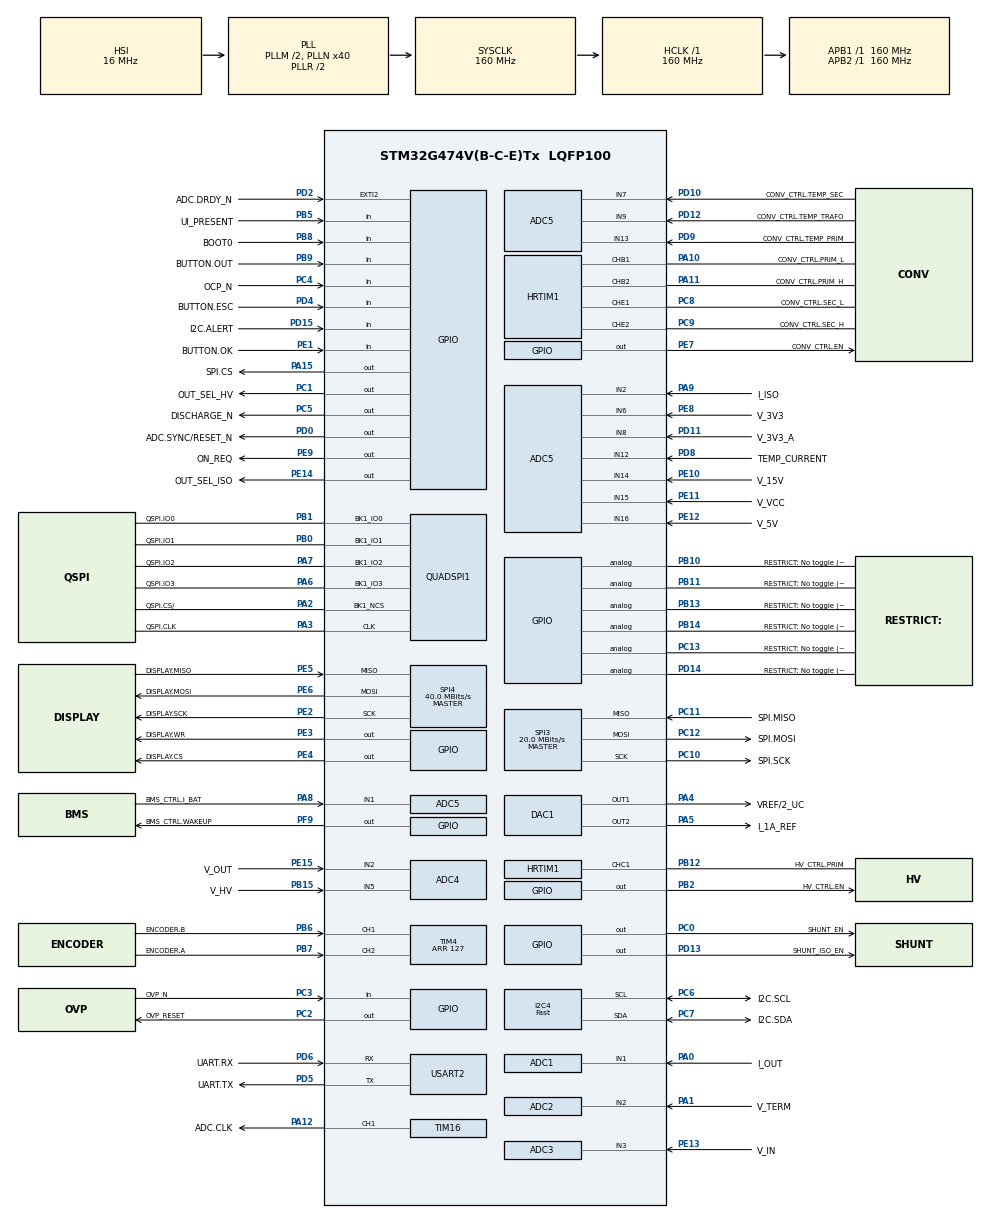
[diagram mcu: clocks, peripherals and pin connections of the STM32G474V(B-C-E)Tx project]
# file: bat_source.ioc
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ADC1.Channel-2\#ChannelRegularConversion=ADC_CHANNEL_1
ADC1.DMAContinuousRequests=ENABLE
ADC1.ExternalTrigConv=ADC_EXTERNALTRIG_HRTIM_TRG1
ADC1.NbrOfConversion=1
ADC1.NbrOfConversionFlag=1
ADC1.OffsetNumber-2\#ChannelRegularConversion=ADC_OFFSET_NONE
ADC1.Rank-2\#ChannelRegularConversion=1
ADC1.SamplingTime-2\#ChannelRegularConversion=ADC_SAMPLETIME_2CYCLES_5
ADC1.master=1
ADC2.Channel-0\#ChannelRegularConversion=ADC_CHANNEL_2
ADC2.DMAContinuousRequests=ENABLE
ADC2.ExternalTrigConv=ADC_EXTERNALTRIG_HRTIM_TRG1
ADC2.NbrOfConversionFlag=1
ADC2.OffsetNumber-0\#ChannelRegularConversion=ADC_OFFSET_NONE
ADC2.Rank-0\#ChannelRegularConversion=1
ADC2.SamplingTime-0\#ChannelRegularConversion=ADC_SAMPLETIME_2CYCLES_5
ADC3.Channel-2\#ChannelRegularConversion=ADC_CHANNEL_3
ADC3.DMAContinuousRequests=ENABLE
ADC3.EnableRegularConversion=ENABLE
ADC3.ExternalTrigConv=ADC_EXTERNALTRIG_HRTIM_TRG1
ADC3.NbrOfConversionFlag=1
ADC3.OffsetNumber-2\#ChannelRegularConversion=ADC_OFFSET_NONE
ADC3.Rank-2\#ChannelRegularConversion=1
ADC3.SamplingTime-2\#ChannelRegularConversion=ADC_SAMPLETIME_2CYCLES_5
ADC3.master=1
ADC4.Channel-0\#ChannelRegularConversion=ADC_CHANNEL_5
ADC4.DMAContinuousRequests=ENABLE
ADC4.EnableInjectedConversion=DISABLE
ADC4.ExternalTrigConv=ADC_EXTERNALTRIG_HRTIM_TRG1
ADC4.NbrOfConversionFlag=1
ADC4.OffsetNumber-0\#ChannelRegularConversion=ADC_OFFSET_NONE
ADC4.Rank-0\#ChannelRegularConversion=1
ADC4.Rank1_Channel=ADC_CHANNEL_2
ADC4.SamplingTime-0\#ChannelRegularConversion=ADC_SAMPLETIME_2CYCLES_5
ADC5.Channel-0\#ChannelRegularConversion=ADC_CHANNEL_6
ADC5.Channel-10\#ChannelRegularConversion=ADC_CHANNEL_TEMPSENSOR_ADC5
ADC5.Channel-11\#ChannelRegularConversion=ADC_CHANNEL_VBAT
ADC5.Channel-12\#ChannelRegularConversion=ADC_CHANNEL_VREFINT
ADC5.Channel-2\#ChannelRegularConversion=ADC_CHANNEL_7
ADC5.Channel-3\#ChannelRegularConversion=ADC_CHANNEL_8
ADC5.Channel-4\#ChannelRegularConversion=ADC_CHANNEL_9
ADC5.Channel-5\#ChannelRegularConversion=ADC_CHANNEL_12
ADC5.Channel-6\#ChannelRegularConversion=ADC_CHANNEL_13
ADC5.Channel-7\#ChannelRegularConversion=ADC_CHANNEL_14
ADC5.Channel-8\#ChannelRegularConversion=ADC_CHANNEL_15
ADC5.Channel-9\#ChannelRegularConversion=ADC_CHANNEL_16
ADC5.ContinuousConvMode=ENABLE
ADC5.DMAContinuousRequests=ENABLE
ADC5.DiscontinuousConvMode=DISABLE
ADC5.EOCSelection=ADC_EOC_SINGLE_CONV
ADC5.EnableInjectedConversion=ENABLE
ADC5.ExternalTrigInjecConv=ADC_EXTERNALTRIGINJEC_HRTIM_TRG1
ADC5.InjNumberOfConversion=1
ADC5.InjectedChannel-13\#ChannelInjectedConversion=ADC_CHANNEL_1
ADC5.InjectedOffsetNumber-13\#ChannelInjectedConversion=ADC_OFFSET_NONE
ADC5.InjectedRank-13\#ChannelInjectedConversion=1
ADC5.InjectedSamplingTime-13\#ChannelInjectedConversion=ADC_SAMPLETIME_2CYCLES_5
ADC5.NbrOfConversion=12
ADC5.NbrOfConversionFlag=1
ADC5.OffsetNumber-0\#ChannelRegularConversion=ADC_OFFSET_NONE
ADC5.OffsetNumber-10\#ChannelRegularConversion=ADC_OFFSET_NONE
ADC5.OffsetNumber-11\#ChannelRegularConversion=ADC_OFFSET_NONE
ADC5.OffsetNumber-12\#ChannelRegularConversion=ADC_OFFSET_NONE
ADC5.OffsetNumber-2\#ChannelRegularConversion=ADC_OFFSET_NONE
ADC5.OffsetNumber-3\#ChannelRegularConversion=ADC_OFFSET_NONE
ADC5.OffsetNumber-4\#ChannelRegularConversion=ADC_OFFSET_NONE
ADC5.OffsetNumber-5\#ChannelRegularConversion=ADC_OFFSET_NONE
ADC5.OffsetNumber-6\#ChannelRegularConversion=ADC_OFFSET_NONE
ADC5.OffsetNumber-7\#ChannelRegularConversion=ADC_OFFSET_NONE
ADC5.OffsetNumber-8\#ChannelRegularConversion=ADC_OFFSET_NONE
ADC5.OffsetNumber-9\#ChannelRegularConversion=ADC_OFFSET_NONE
ADC5.OversamplingMode=ENABLE
ADC5.Rank-0\#ChannelRegularConversion=1
ADC5.Rank-10\#ChannelRegularConversion=10
ADC5.Rank-11\#ChannelRegularConversion=11
ADC5.Rank-12\#ChannelRegularConversion=12
ADC5.Rank-2\#ChannelRegularConversion=2
ADC5.Rank-3\#ChannelRegularConversion=3
ADC5.Rank-4\#ChannelRegularConversion=4
ADC5.Rank-5\#ChannelRegularConversion=5
ADC5.Rank-6\#ChannelRegularConversion=6
ADC5.Rank-7\#ChannelRegularConversion=7
ADC5.Rank-8\#ChannelRegularConversion=8
ADC5.Rank-9\#ChannelRegularConversion=9
ADC5.Rank1_Channel=ADC_CHANNEL_1
ADC5.Ratio=ADC_OVERSAMPLING_RATIO_256
ADC5.RightBitShift=ADC_RIGHTBITSHIFT_4
ADC5.SamplingTime-0\#ChannelRegularConversion=ADC_SAMPLETIME_2CYCLES_5
ADC5.SamplingTime-10\#ChannelRegularConversion=ADC_SAMPLETIME_2CYCLES_5
ADC5.SamplingTime-11\#ChannelRegularConversion=ADC_SAMPLETIME_2CYCLES_5
ADC5.SamplingTime-12\#ChannelRegularConversion=ADC_SAMPLETIME_2CYCLES_5
ADC5.SamplingTime-2\#ChannelRegularConversion=ADC_SAMPLETIME_2CYCLES_5
ADC5.SamplingTime-3\#ChannelRegularConversion=ADC_SAMPLETIME_2CYCLES_5
ADC5.SamplingTime-4\#ChannelRegularConversion=ADC_SAMPLETIME_2CYCLES_5
ADC5.SamplingTime-5\#ChannelRegularConversion=ADC_SAMPLETIME_2CYCLES_5
ADC5.SamplingTime-6\#ChannelRegularConversion=ADC_SAMPLETIME_2CYCLES_5
ADC5.SamplingTime-7\#ChannelRegularConversion=ADC_SAMPLETIME_2CYCLES_5
ADC5.SamplingTime-8\#ChannelRegularConversion=ADC_SAMPLETIME_2CYCLES_5
ADC5.SamplingTime-9\#ChannelRegularConversion=ADC_SAMPLETIME_2CYCLES_5
DAC1.DAC_Channel-DAC_OUT2=DAC_CHANNEL_2
Dma.ADC1.1.Direction=DMA_PERIPH_TO_MEMORY
Dma.ADC1.1.EventEnable=DISABLE
Dma.ADC1.1.Instance=DMA1_Channel2
Dma.ADC1.1.MemDataAlignment=DMA_MDATAALIGN_HALFWORD
Dma.ADC1.1.MemInc=DMA_MINC_ENABLE
Dma.ADC1.1.Mode=DMA_CIRCULAR
Dma.ADC1.1.PeriphDataAlignment=DMA_PDATAALIGN_HALFWORD
Dma.ADC1.1.PeriphInc=DMA_PINC_DISABLE
Dma.ADC1.1.Polarity=HAL_DMAMUX_REQ_GEN_RISING
Dma.ADC1.1.Priority=DMA_PRIORITY_LOW
Dma.ADC1.1.RequestNumber=1
Dma.ADC1.1.SignalID=NONE
Dma.ADC1.1.SyncEnable=DISABLE
Dma.ADC1.1.SyncPolarity=HAL_DMAMUX_SYNC_NO_EVENT
Dma.ADC1.1.SyncRequestNumber=1
Dma.ADC1.1.SyncSignalID=NONE
Dma.ADC2.2.Direction=DMA_PERIPH_TO_MEMORY
Dma.ADC2.2.EventEnable=DISABLE
Dma.ADC2.2.Instance=DMA1_Channel3
Dma.ADC2.2.MemDataAlignment=DMA_MDATAALIGN_HALFWORD
Dma.ADC2.2.MemInc=DMA_MINC_ENABLE
Dma.ADC2.2.Mode=DMA_CIRCULAR
Dma.ADC2.2.PeriphDataAlignment=DMA_PDATAALIGN_HALFWORD
Dma.ADC2.2.PeriphInc=DMA_PINC_DISABLE
Dma.ADC2.2.Polarity=HAL_DMAMUX_REQ_GEN_RISING
Dma.ADC2.2.Priority=DMA_PRIORITY_LOW
Dma.ADC2.2.RequestNumber=1
Dma.ADC2.2.SignalID=NONE
Dma.ADC2.2.SyncEnable=DISABLE
Dma.ADC2.2.SyncPolarity=HAL_DMAMUX_SYNC_NO_EVENT
Dma.ADC2.2.SyncRequestNumber=1
Dma.ADC2.2.SyncSignalID=NONE
Dma.ADC3.3.Direction=DMA_PERIPH_TO_MEMORY
Dma.ADC3.3.EventEnable=DISABLE
Dma.ADC3.3.Instance=DMA1_Channel4
Dma.ADC3.3.MemDataAlignment=DMA_MDATAALIGN_HALFWORD
Dma.ADC3.3.MemInc=DMA_MINC_ENABLE
Dma.ADC3.3.Mode=DMA_CIRCULAR
Dma.ADC3.3.PeriphDataAlignment=DMA_PDATAALIGN_HALFWORD
Dma.ADC3.3.PeriphInc=DMA_PINC_DISABLE
Dma.ADC3.3.Polarity=HAL_DMAMUX_REQ_GEN_RISING
Dma.ADC3.3.Priority=DMA_PRIORITY_LOW
Dma.ADC3.3.RequestNumber=1
Dma.ADC3.3.SignalID=NONE
Dma.ADC3.3.SyncEnable=DISABLE
Dma.ADC3.3.SyncPolarity=HAL_DMAMUX_SYNC_NO_EVENT
Dma.ADC3.3.SyncRequestNumber=1
Dma.ADC3.3.SyncSignalID=NONE
Dma.ADC4.4.Direction=DMA_PERIPH_TO_MEMORY
Dma.ADC4.4.EventEnable=DISABLE
Dma.ADC4.4.Instance=DMA1_Channel5
Dma.ADC4.4.MemDataAlignment=DMA_MDATAALIGN_HALFWORD
Dma.ADC4.4.MemInc=DMA_MINC_ENABLE
Dma.ADC4.4.Mode=DMA_CIRCULAR
Dma.ADC4.4.PeriphDataAlignment=DMA_PDATAALIGN_HALFWORD
Dma.ADC4.4.PeriphInc=DMA_PINC_DISABLE
Dma.ADC4.4.Polarity=HAL_DMAMUX_REQ_GEN_RISING
Dma.ADC4.4.Priority=DMA_PRIORITY_LOW
Dma.ADC4.4.RequestNumber=1
Dma.ADC4.4.SignalID=NONE
Dma.ADC4.4.SyncEnable=DISABLE
Dma.ADC4.4.SyncPolarity=HAL_DMAMUX_SYNC_NO_EVENT
Dma.ADC4.4.SyncRequestNumber=1
Dma.ADC4.4.SyncSignalID=NONE
Dma.ADC5.0.Direction=DMA_PERIPH_TO_MEMORY
Dma.ADC5.0.EventEnable=DISABLE
Dma.ADC5.0.Instance=DMA1_Channel1
Dma.ADC5.0.MemDataAlignment=DMA_MDATAALIGN_HALFWORD
Dma.ADC5.0.MemInc=DMA_MINC_ENABLE
Dma.ADC5.0.Mode=DMA_CIRCULAR
Dma.ADC5.0.PeriphDataAlignment=DMA_PDATAALIGN_HALFWORD
Dma.ADC5.0.PeriphInc=DMA_PINC_DISABLE
Dma.ADC5.0.Polarity=HAL_DMAMUX_REQ_GEN_RISING
Dma.ADC5.0.Priority=DMA_PRIORITY_LOW
Dma.ADC5.0.RequestNumber=1
Dma.ADC5.0.SignalID=NONE
Dma.ADC5.0.SyncEnable=DISABLE
Dma.ADC5.0.SyncPolarity=HAL_DMAMUX_SYNC_NO_EVENT
Dma.ADC5.0.SyncRequestNumber=1
Dma.ADC5.0.SyncSignalID=NONE
Dma.I2C4_RX.7.Direction=DMA_PERIPH_TO_MEMORY
Dma.I2C4_RX.7.EventEnable=DISABLE
Dma.I2C4_RX.7.Instance=DMA1_Channel8
Dma.I2C4_RX.7.MemDataAlignment=DMA_MDATAALIGN_BYTE
Dma.I2C4_RX.7.MemInc=DMA_MINC_ENABLE
Dma.I2C4_RX.7.Mode=DMA_NORMAL
Dma.I2C4_RX.7.PeriphDataAlignment=DMA_PDATAALIGN_BYTE
Dma.I2C4_RX.7.PeriphInc=DMA_PINC_DISABLE
Dma.I2C4_RX.7.Polarity=HAL_DMAMUX_REQ_GEN_RISING
Dma.I2C4_RX.7.Priority=DMA_PRIORITY_LOW
Dma.I2C4_RX.7.RequestNumber=1
Dma.I2C4_RX.7.SignalID=NONE
Dma.I2C4_RX.7.SyncEnable=DISABLE
Dma.I2C4_RX.7.SyncPolarity=HAL_DMAMUX_SYNC_NO_EVENT
Dma.I2C4_RX.7.SyncRequestNumber=1
Dma.I2C4_RX.7.SyncSignalID=NONE
Dma.I2C4_TX.8.Direction=DMA_MEMORY_TO_PERIPH
Dma.I2C4_TX.8.EventEnable=DISABLE
Dma.I2C4_TX.8.Instance=DMA2_Channel1
Dma.I2C4_TX.8.MemDataAlignment=DMA_MDATAALIGN_BYTE
Dma.I2C4_TX.8.MemInc=DMA_MINC_ENABLE
Dma.I2C4_TX.8.Mode=DMA_NORMAL
Dma.I2C4_TX.8.PeriphDataAlignment=DMA_PDATAALIGN_BYTE
Dma.I2C4_TX.8.PeriphInc=DMA_PINC_DISABLE
Dma.I2C4_TX.8.Polarity=HAL_DMAMUX_REQ_GEN_RISING
Dma.I2C4_TX.8.Priority=DMA_PRIORITY_LOW
Dma.I2C4_TX.8.RequestNumber=1
Dma.I2C4_TX.8.SignalID=NONE
Dma.I2C4_TX.8.SyncEnable=DISABLE
Dma.I2C4_TX.8.SyncPolarity=HAL_DMAMUX_SYNC_NO_EVENT
Dma.I2C4_TX.8.SyncRequestNumber=1
Dma.I2C4_TX.8.SyncSignalID=NONE
Dma.Request0=ADC5
Dma.Request1=ADC1
Dma.Request2=ADC2
Dma.Request3=ADC3
Dma.Request4=ADC4
Dma.Request5=SPI3_RX
Dma.Request6=SPI3_TX
Dma.Request7=I2C4_RX
Dma.Request8=I2C4_TX
Dma.Request9=SPI4_TX
Dma.SPI3_RX.5.Direction=DMA_PERIPH_TO_MEMORY
Dma.SPI3_RX.5.EventEnable=DISABLE
Dma.SPI3_RX.5.Instance=DMA1_Channel6
Dma.SPI3_RX.5.MemDataAlignment=DMA_MDATAALIGN_BYTE
Dma.SPI3_RX.5.MemInc=DMA_MINC_ENABLE
Dma.SPI3_RX.5.Mode=DMA_NORMAL
Dma.SPI3_RX.5.PeriphDataAlignment=DMA_PDATAALIGN_BYTE
Dma.SPI3_RX.5.PeriphInc=DMA_PINC_DISABLE
Dma.SPI3_RX.5.Polarity=HAL_DMAMUX_REQ_GEN_RISING
Dma.SPI3_RX.5.Priority=DMA_PRIORITY_LOW
Dma.SPI3_RX.5.RequestNumber=1
Dma.SPI3_RX.5.SignalID=NONE
Dma.SPI3_RX.5.SyncEnable=DISABLE
Dma.SPI3_RX.5.SyncPolarity=HAL_DMAMUX_SYNC_NO_EVENT
Dma.SPI3_RX.5.SyncRequestNumber=1
Dma.SPI3_RX.5.SyncSignalID=NONE
Dma.SPI3_TX.6.Direction=DMA_MEMORY_TO_PERIPH
Dma.SPI3_TX.6.EventEnable=DISABLE
Dma.SPI3_TX.6.Instance=DMA1_Channel7
Dma.SPI3_TX.6.MemDataAlignment=DMA_MDATAALIGN_BYTE
Dma.SPI3_TX.6.MemInc=DMA_MINC_ENABLE
Dma.SPI3_TX.6.Mode=DMA_NORMAL
Dma.SPI3_TX.6.PeriphDataAlignment=DMA_PDATAALIGN_BYTE
Dma.SPI3_TX.6.PeriphInc=DMA_PINC_DISABLE
Dma.SPI3_TX.6.Polarity=HAL_DMAMUX_REQ_GEN_RISING
Dma.SPI3_TX.6.Priority=DMA_PRIORITY_LOW
Dma.SPI3_TX.6.RequestNumber=1
Dma.SPI3_TX.6.SignalID=NONE
Dma.SPI3_TX.6.SyncEnable=DISABLE
Dma.SPI3_TX.6.SyncPolarity=HAL_DMAMUX_SYNC_NO_EVENT
Dma.SPI3_TX.6.SyncRequestNumber=1
Dma.SPI3_TX.6.SyncSignalID=NONE
Dma.SPI4_TX.9.Direction=DMA_MEMORY_TO_PERIPH
Dma.SPI4_TX.9.EventEnable=DISABLE
Dma.SPI4_TX.9.Instance=DMA2_Channel2
Dma.SPI4_TX.9.MemDataAlignment=DMA_MDATAALIGN_BYTE
Dma.SPI4_TX.9.MemInc=DMA_MINC_ENABLE
Dma.SPI4_TX.9.Mode=DMA_NORMAL
Dma.SPI4_TX.9.PeriphDataAlignment=DMA_PDATAALIGN_BYTE
Dma.SPI4_TX.9.PeriphInc=DMA_PINC_DISABLE
Dma.SPI4_TX.9.Polarity=HAL_DMAMUX_REQ_GEN_RISING
Dma.SPI4_TX.9.Priority=DMA_PRIORITY_LOW
Dma.SPI4_TX.9.RequestNumber=1
Dma.SPI4_TX.9.SignalID=NONE
Dma.SPI4_TX.9.SyncEnable=DISABLE
Dma.SPI4_TX.9.SyncPolarity=HAL_DMAMUX_SYNC_NO_EVENT
Dma.SPI4_TX.9.SyncRequestNumber=1
Dma.SPI4_TX.9.SyncSignalID=NONE
HRTIM1.ADCTrigger1_Source1=HRTIM_ADCTRIGGEREVENT13_TIMERB_PERIOD
HRTIM1.ADCTrigger3_Source1=HRTIM_ADCTRIGGEREVENT13_TIMERE_PERIOD
HRTIM1.ADCTrigger_Id1=HRTIM_ADCTRIGGER_1
HRTIM1.ADCTrigger_Id2=__NULL
HRTIM1.ADCTrigger_Id3=HRTIM_ADCTRIGGER_3
HRTIM1.ADCTrigger_Id5=HRTIM_ADCTRIGGER_5
HRTIM1.ADCTrigger_Id6=__NULL
HRTIM1.ADCTrigger_Id7=HRTIM_ADCTRIGGER_7
HRTIM1.ADCTrigger_Id8=__NULL
HRTIM1.Adrom_TB=HRTIM_TIM_ADROM_CREST
HRTIM1.Adrom_TC=HRTIM_TIM_ADROM_CREST
HRTIM1.Adrom_TD=HRTIM_TIM_ADROM_CREST
HRTIM1.Adrom_TE=HRTIM_TIM_ADROM_CREST
HRTIM1.BURSTMODEPeriod=20
HRTIM1.BurstPreloadEnable=HRIM_BURSTMODEPRELOAD_DISABLED
HRTIM1.ClockSource=HRTIM_BURSTMODECLOCKSOURCE_TIMER_D
HRTIM1.CompareUnit1-MasterTimer=HRTIM_COMPAREUNIT_1
HRTIM1.CompareUnit1-Output_TB1TB2=HRTIM_COMPAREUNIT_1
HRTIM1.CompareUnit1-Output_TC1=HRTIM_COMPAREUNIT_1
HRTIM1.CompareUnit1-Output_TE1TE2=HRTIM_COMPAREUNIT_1
HRTIM1.CompareUnit2-MasterTimer=HRTIM_COMPAREUNIT_2
HRTIM1.CompareUnit2-Output_TB1TB2=__NULL
HRTIM1.CompareUnit3-MasterTimer=HRTIM_COMPAREUNIT_3
HRTIM1.CompareValue1-MasterTimer=5120
HRTIM1.CompareValue1-Output_TB1TB2=0x60
HRTIM1.CompareValue1-Output_TC1=0x1555
HRTIM1.CompareValue1-Output_TE1TE2=0x300
HRTIM1.CompareValue2-MasterTimer=26880
HRTIM1.CompareValue3-MasterTimer=30720
HRTIM1.Configuration_TB=Waveform
HRTIM1.Configuration_TC=Waveform
HRTIM1.Configuration_TD=Simple
HRTIM1.DeadTimeInsertion-Output_TB1TB2=HRTIM_TIMDEADTIMEINSERTION_ENABLED
HRTIM1.DeadTimeInsertion-Output_TE1TE2=HRTIM_TIMDEADTIMEINSERTION_ENABLED
HRTIM1.Deadtimeconfig-Output_TB1TB2=HRTIM_TIMERINDEX_TIMER_B
HRTIM1.Enable=HRTIM_BURSTMODECTL_ENABLED
HRTIM1.Event_EEV1=__NULL
HRTIM1.FallingLock-Output_TB1TB2=HRTIM_TIMDEADTIME_FALLINGLOCK_READONLY
HRTIM1.FallingLock-Output_TE1TE2=HRTIM_TIMDEADTIME_FALLINGLOCK_READONLY
HRTIM1.FallingSignLock-Output_TB1TB2=HRTIM_TIMDEADTIME_FALLINGSIGNLOCK_READONLY
HRTIM1.FallingSignLock-Output_TE1TE2=HRTIM_TIMDEADTIME_FALLINGSIGNLOCK_READONLY
HRTIM1.FallingValue-Output_TB1TB2=0x00A
HRTIM1.FallingValue-Output_TE1TE2=0x00A
HRTIM1.GreaterCMP1_TB=HRTIM_TIMERGTCMP1_EQUAL
HRTIM1.GreaterCMP1_TE=HRTIM_TIMERGTCMP1_EQUAL
HRTIM1.Mode=HRTIM_BURSTMODE_CONTINOUS
HRTIM1.ModeTimeBase-Output_TE1TE2=HRTIM_MODE_CONTINUOUS
HRTIM1.NumberADCTriggerSource1=1
HRTIM1.NumberADCTriggerSource3=1
HRTIM1.NumberResetSource1-Output_TB1TB2=1
HRTIM1.NumberResetSource1-Output_TC1=1
HRTIM1.NumberResetSource1-Output_TE1TE2=1
HRTIM1.NumberResetTrigger-Output_TB1TB2=0
HRTIM1.NumberResetTrigger-Output_TE1TE2=0
HRTIM1.NumberSetSource1-Output_TB1TB2=1
HRTIM1.NumberSetSource1-Output_TC1=0
HRTIM1.NumberSetSource1-Output_TE1TE2=0
HRTIM1.NumberUpdateTrigger-Output_TB1TB2=1
HRTIM1.NumberUpdateTrigger-Output_TE1TE2=1
HRTIM1.ORingUpdateSource_ADCTrigger1=HRTIM_ADCTRIGGERUPDATE_TIMER_B
HRTIM1.ORingUpdateSource_ADCTrigger3=HRTIM_ADCTRIGGERUPDATE_TIMER_E
HRTIM1.ORingUpdateSource_ADCTrigger5=HRTIM_ADCTRIGGERUPDATE_TIMER_C
HRTIM1.ORingUpdateSource_ADCTrigger7=HRTIM_ADCTRIGGERUPDATE_TIMER_D
HRTIM1.Periode_MASTER=51200
HRTIM1.Periode_TB=51200
HRTIM1.Periode_TC=0x3924
HRTIM1.Periode_TD=2560
HRTIM1.Periode_TE=0xC800
HRTIM1.PreloadEnable-Output_TB1TB2=HRTIM_PRELOAD_ENABLED
HRTIM1.PreloadEnable-Output_TE1TE2=HRTIM_PRELOAD_ENABLED
HRTIM1.PrescalerRatio_MASTER=HRTIM_PRESCALERRATIO_MUL16
HRTIM1.PrescalerRatio_TE=HRTIM_PRESCALERRATIO_MUL32
HRTIM1.ReSyncUpdate-Output_TB1TB2=HRTIM_TIMERESYNC_UPDATE_CONDITIONAL
HRTIM1.ReSyncUpdate-Output_TE1TE2=HRTIM_TIMERESYNC_UPDATE_CONDITIONAL
HRTIM1.RepetitionUpdate-Output_TB1TB2=HRTIM_UPDATEONREPETITION_DISABLED
HRTIM1.ResetOutput1_Source1-Output_TC1=HRTIM_OUTPUTRESET_TIMCMP1
HRTIM1.ResetOutput1_Source1-Output_TE1TE2=HRTIM_OUTPUTRESET_TIMCMP1
HRTIM1.ResetUpdate-Output_TB1TB2=HRTIM_TIMUPDATEONRESET_ENABLED
HRTIM1.ResetUpdate-Output_TE1TE2=HRTIM_TIMUPDATEONRESET_ENABLED
HRTIM1.RisingLock-Output_TB1TB2=HRTIM_TIMDEADTIME_RISINGLOCK_READONLY
HRTIM1.RisingLock-Output_TE1TE2=HRTIM_TIMDEADTIME_RISINGLOCK_READONLY
HRTIM1.RisingSignLock-Output_TB1TB2=HRTIM_TIMDEADTIME_RISINGSIGNLOCK_READONLY
HRTIM1.RisingSignLock-Output_TE1TE2=HRTIM_TIMDEADTIME_RISINGSIGNLOCK_READONLY
HRTIM1.RisingValue-Output_TB1TB2=0x00A
HRTIM1.RisingValue-Output_TE1TE2=0x00A
HRTIM1.SetOutput1_Source1-Output_TB1TB2=HRTIM_OUTPUTSET_TIMCMP1
HRTIM1.Source_ADCTrigger5=HRTIM_ADCTRIGGEREVENT579_TIMERC_PERIOD
HRTIM1.Source_ADCTrigger7=HRTIM_ADCTRIGGEREVENT579_TIMERD_PERIOD
HRTIM1.UpDownMode-No_output_TD=HRTIM_TIMERUPDOWNMODE_UPDOWN
HRTIM1.UpDownMode-Output_TB1TB2=HRTIM_TIMERUPDOWNMODE_UPDOWN
HRTIM1.UpDownMode-Output_TC1=HRTIM_TIMERUPDOWNMODE_UPDOWN
HRTIM1.UpDownMode-Output_TE1TE2=HRTIM_TIMERUPDOWNMODE_UPDOWN
HRTIM1.UpdateTrigger1-Output_TB1TB2=HRTIM_TIMUPDATETRIGGER_TIMER_B
HRTIM1.UpdateTrigger1-Output_TE1TE2=HRTIM_TIMUPDATETRIGGER_TIMER_E
HRTIM1.postscaler1=19
HRTIM1.postscaler3=19
HRTIM1.postscaler5=0x6
HRTIM1.postscaler7=19
I2C4.I2C_Speed_Mode=I2C_Fast
I2C4.Speed=400
I2C4.Timing=0x10F32A82
Mcu.Family=STM32G4
Mcu.Name=STM32G474V(B-C-E)Tx
Mcu.Package=LQFP100
NVIC.DMA1_Channel1_IRQn=true\:4\:0\:false\:false\:true\:false\:true\:true
NVIC.DMA1_Channel2_IRQn=true\:0\:0\:false\:false\:true\:false\:true\:true
NVIC.DMA1_Channel3_IRQn=true\:4\:0\:false\:false\:true\:false\:true\:true
NVIC.DMA1_Channel4_IRQn=true\:4\:0\:false\:false\:true\:false\:true\:true
NVIC.DMA1_Channel5_IRQn=true\:4\:0\:false\:false\:true\:false\:true\:true
NVIC.DMA1_Channel6_IRQn=true\:4\:0\:false\:false\:true\:false\:true\:true
NVIC.DMA1_Channel7_IRQn=true\:4\:0\:false\:false\:true\:false\:true\:true
NVIC.DMA1_Channel8_IRQn=true\:8\:0\:false\:false\:true\:false\:true\:true
NVIC.DMA2_Channel1_IRQn=true\:8\:0\:false\:false\:true\:false\:true\:true
NVIC.DMA2_Channel2_IRQn=true\:8\:0\:false\:false\:true\:false\:true\:true
NVIC.EXTI2_IRQn=true\:4\:0\:false\:false\:true\:true\:true\:false
NVIC.I2C4_ER_IRQn=true\:8\:0\:false\:false\:true\:true\:true\:true
NVIC.I2C4_EV_IRQn=true\:8\:0\:false\:false\:true\:true\:true\:true
NVIC.PriorityGroup=NVIC_PRIORITYGROUP_4
NVIC.SPI3_IRQn=true\:4\:0\:false\:false\:true\:true\:true\:true
NVIC.SPI4_IRQn=true\:8\:0\:false\:false\:true\:true\:true\:true
NVIC.TIM2_IRQn=true\:8\:0\:false\:false\:true\:true\:true\:true
NVIC.TIM6_DAC_IRQn=true\:8\:0\:false\:false\:true\:true\:true\:true
PA0.GPIO_Label=I_OUT
PA0.Mode=IN1-Single-Ended
PA0.Signal=ADC1_IN1
PA1.GPIO_Label=V_TERM
PA1.Mode=IN2-Single-Ended
PA1.Signal=ADC2_IN2
PA10.GPIO_Label=CONV_CTRL.PRIM_L
PA10.Mode=Output_TB1TB2
PA10.Signal=HRTIM1_CHB1
PA11.GPIO_Label=CONV_CTRL.PRIM_H
PA11.Mode=Output_TB1TB2
PA11.Signal=HRTIM1_CHB2
PA12.GPIO_Label=ADC.CLK
PA12.GPIO_Speed=GPIO_SPEED_FREQ_VERY_HIGH
PA12.Signal=S_TIM16_CH1
PA13.GPIO_Label=SWD.SWDAT
PA13.Mode=Trace_Asynchronous_SW
PA13.Signal=SYS_JTMS-SWDIO
PA14.GPIO_Label=SWD.SWCLK
PA14.Mode=Trace_Asynchronous_SW
PA14.Signal=SYS_JTCK-SWCLK
PA15.GPIO_Label=SPI.CS
PA15.GPIO_Speed=GPIO_SPEED_FREQ_VERY_HIGH
PA15.Signal=GPIO_Output
PA2.GPIO_Label=QSPI.CS/
PA2.GPIO_Speed=GPIO_SPEED_FREQ_VERY_HIGH
PA2.Mode=Single Bank 1
PA2.Signal=QUADSPI1_BK1_NCS
PA3.GPIO_Label=QSPI.CLK
PA3.GPIO_Speed=GPIO_SPEED_FREQ_VERY_HIGH
PA3.Mode=Single Bank 1
PA3.Signal=QUADSPI1_CLK
PA4.GPIO_Label=VREF/2_UC
PA4.Signal=COMP_DAC11_group
PA5.GPIO_Label=I_1A_REF
PA5.Signal=COMP_DAC12_group
PA6.GPIO_Label=QSPI.IO3
PA6.GPIO_Speed=GPIO_SPEED_FREQ_VERY_HIGH
PA6.Mode=Single Bank 1
PA6.Signal=QUADSPI1_BK1_IO3
PA7.GPIO_Label=QSPI.IO2
PA7.GPIO_Speed=GPIO_SPEED_FREQ_VERY_HIGH
PA7.Mode=Single Bank 1
PA7.Signal=QUADSPI1_BK1_IO2
PA8.GPIO_Label=BMS_CTRL.I_BAT
PA8.Mode=IN1-Single-Ended
PA8.Signal=ADC5_IN1
PA9.GPIO_Label=I_ISO
PA9.Mode=IN2-Single-Ended
PA9.Signal=ADC5_IN2
PB0.GPIO_Label=QSPI.IO1
PB0.GPIO_Speed=GPIO_SPEED_FREQ_VERY_HIGH
PB0.Mode=Single Bank 1
PB0.Signal=QUADSPI1_BK1_IO1
PB1.GPIO_Label=QSPI.IO0
PB1.GPIO_Speed=GPIO_SPEED_FREQ_VERY_HIGH
PB1.Mode=Single Bank 1
PB1.Signal=QUADSPI1_BK1_IO0
PB10.GPIO_Label=RESTRICT\: No toggle (REFBUF)
PB10.Signal=GPIO_Analog
PB11.GPIO_Label=RESTRICT\: No toggle (REFBUF)
PB11.Signal=GPIO_Analog
PB12.GPIO_Label=HV_CTRL.PRIM
PB12.Mode=Output_TC1
PB12.Signal=HRTIM1_CHC1
PB13.GPIO_Label=RESTRICT\: No toggle (REFBUF)
PB13.Signal=GPIO_Analog
PB14.GPIO_Label=RESTRICT\: No toggle (REFBUF)
PB14.Signal=GPIO_Analog
PB15.GPIO_Label=V_HV
PB15.Mode=IN5-Single-Ended
PB15.Signal=ADC4_IN5
PB2.GPIO_Label=HV_CTRL.EN
PB2.Signal=GPIO_Output
PB3.GPIO_Label=SWD.SWO
PB3.Mode=Trace_Asynchronous_SW
PB3.Signal=SYS_JTDO-SWO
PB5.GPIO_Label=UI_PRESENT
PB5.Signal=GPIO_Input
PB6.GPIO_Label=ENCODER.B
PB6.Signal=S_TIM4_CH1
PB7.GPIO_Label=ENCODER.A
PB7.Signal=S_TIM4_CH2
PB8-BOOT0.GPIO_Label=BOOT0
PB8-BOOT0.Signal=GPIO_Input
PB9.GPIO_Label=BUTTON.OUT
PB9.Signal=GPIO_Input
PC0.GPIO_Label=SHUNT_EN
PC0.PinState=GPIO_PIN_SET
PC0.Signal=GPIO_Output
PC1.GPIO_Label=OUT_SEL_HV
PC1.Signal=GPIO_Output
PC10.GPIO_Label=SPI.SCK
PC10.GPIO_Speed=GPIO_SPEED_FREQ_VERY_HIGH
PC10.Mode=Full_Duplex_Master
PC10.Signal=SPI3_SCK
PC11.GPIO_Label=SPI.MISO
PC11.GPIO_Speed=GPIO_SPEED_FREQ_VERY_HIGH
PC11.Mode=Full_Duplex_Master
PC11.Signal=SPI3_MISO
PC12.GPIO_Label=SPI.MOSI
PC12.GPIO_Speed=GPIO_SPEED_FREQ_VERY_HIGH
PC12.Mode=Full_Duplex_Master
PC12.Signal=SPI3_MOSI
PC13.GPIO_Label=RESTRICT\: No toggle (LSE)
PC13.Signal=GPIO_Analog
PC14-OSC32_IN.Mode=LSE-External-Oscillator
PC14-OSC32_IN.Signal=RCC_OSC32_IN
PC15-OSC32_OUT.Mode=LSE-External-Oscillator
PC15-OSC32_OUT.Signal=RCC_OSC32_OUT
PC2.GPIO_Label=OVP_RESET
PC2.Signal=GPIO_Output
PC3.GPIO_Label=OVP_N
PC3.Signal=GPIO_Input
PC4.GPIO_Label=OCP_N
PC4.Signal=GPIO_Input
PC5.GPIO_Label=DISCHARGE_N
PC5.PinState=GPIO_PIN_SET
PC5.Signal=GPIO_Output
PC6.GPIO_Label=I2C.SCL
PC6.Mode=I2C
PC6.Signal=I2C4_SCL
PC7.GPIO_Label=I2C.SDA
PC7.Mode=I2C
PC7.Signal=I2C4_SDA
PC8.GPIO_Label=CONV_CTRL.SEC_L
PC8.Mode=Output_TE1TE2
PC8.Signal=HRTIM1_CHE1
PC9.GPIO_Label=CONV_CTRL.SEC_H
PC9.Mode=Output_TE1TE2
PC9.Signal=HRTIM1_CHE2
PD0.GPIO_Label=ADC.SYNC/RESET_N
PD0.GPIO_Speed=GPIO_SPEED_FREQ_HIGH
PD0.Signal=GPIO_Output
PD10.GPIO_Label=CONV_CTRL.TEMP_SEC
PD10.Mode=IN7-Single-Ended
PD10.Signal=ADC5_IN7
PD11.GPIO_Label=V_3V3_A
PD11.Mode=IN8-Single-Ended
PD11.Signal=ADC5_IN8
PD12.GPIO_Label=CONV_CTRL.TEMP_TRAFO
PD12.Mode=IN9-Single-Ended
PD12.Signal=ADC5_IN9
PD13.GPIO_Label=SHUNT_ISO_EN
PD13.Signal=GPIO_Output
PD14.GPIO_Label=RESTRICT\: No toggle (REFBUF)
PD14.Signal=GPIO_Analog
PD15.GPIO_Label=I2C.ALERT
PD15.Signal=GPIO_Input
PD2.GPIO_Label=ADC.DRDY_N
PD2.GPIO_ModeDefaultEXTI=GPIO_MODE_IT_FALLING
PD2.Signal=GPXTI2
PD4.GPIO_Label=BUTTON.ESC
PD4.Signal=GPIO_Input
PD5.GPIO_Label=UART.TX
PD5.Mode=Asynchronous
PD5.Signal=USART2_TX
PD6.GPIO_Label=UART.RX
PD6.Mode=Asynchronous
PD6.Signal=USART2_RX
PD8.GPIO_Label=TEMP_CURRENT
PD8.Mode=IN12-Single-Ended
PD8.Signal=ADC5_IN12
PD9.GPIO_Label=CONV_CTRL.TEMP_PRIM
PD9.Mode=IN13-Single-Ended
PD9.Signal=ADC5_IN13
PE1.GPIO_Label=BUTTON.OK
PE1.Signal=GPIO_Input
PE10.GPIO_Label=V_15V
PE10.Mode=IN14-Single-Ended
PE10.Signal=ADC5_IN14
PE11.GPIO_Label=V_VCC
PE11.Mode=IN15-Single-Ended
PE11.Signal=ADC5_IN15
PE12.GPIO_Label=V_5V
PE12.Mode=IN16-Single-Ended
PE12.Signal=ADC5_IN16
PE13.GPIO_Label=V_IN
PE13.Mode=IN3-Single-Ended
PE13.Signal=ADC3_IN3
PE14.GPIO_Label=OUT_SEL_ISO
PE14.Signal=GPIO_Output
PE15.GPIO_Label=V_OUT
PE15.Mode=IN2-Single-Ended
PE15.Signal=ADC4_IN2
PE2.GPIO_Label=DISPLAY.SCK
PE2.GPIO_Speed=GPIO_SPEED_FREQ_VERY_HIGH
PE2.Mode=Full_Duplex_Master
PE2.Signal=SPI4_SCK
PE3.GPIO_Label=DISPLAY.WR
PE3.GPIO_Speed=GPIO_SPEED_FREQ_VERY_HIGH
PE3.Signal=GPIO_Output
PE4.GPIO_Label=DISPLAY.CS
PE4.Signal=GPIO_Output
PE5.GPIO_Label=DISPLAY.MISO
PE5.GPIO_Speed=GPIO_SPEED_FREQ_VERY_HIGH
PE5.Mode=Full_Duplex_Master
PE5.Signal=SPI4_MISO
PE6.GPIO_Label=DISPLAY.MOSI
PE6.GPIO_Speed=GPIO_SPEED_FREQ_VERY_HIGH
PE6.Mode=Full_Duplex_Master
PE6.Signal=SPI4_MOSI
PE7.GPIO_Label=CONV_CTRL.EN
PE7.Signal=GPIO_Output
PE8.GPIO_Label=V_3V3
PE8.Mode=IN6-Single-Ended
PE8.Signal=ADC5_IN6
PE9.GPIO_Label=ON_REQ
PE9.PinState=GPIO_PIN_SET
PE9.Signal=GPIO_Output
PF9.GPIO_Label=BMS_CTRL.WAKEUP
PF9.Signal=GPIO_Output
ProjectManager.HeapSize=0x200
ProjectManager.StackSize=0x1000
ProjectManager.TargetToolchain=STM32CubeIDE
QUADSPI1.ChipSelectHighTime=QSPI_CS_HIGH_TIME_4_CYCLE
QUADSPI1.ClockMode=QSPI_CLOCK_MODE_3
QUADSPI1.ClockPrescaler=1
QUADSPI1.FlashSize=26
RCC.ADC12Freq_Value=160000000
RCC.ADC345Freq_Value=160000000
RCC.AHBFreq_Value=160000000
RCC.APB1Freq_Value=160000000
RCC.APB1TimFreq_Value=160000000
RCC.APB2Freq_Value=160000000
RCC.APB2TimFreq_Value=160000000
RCC.CortexFreq_Value=160000000
RCC.EXTERNAL_CLOCK_VALUE=12288000
RCC.HCLKFreq_Value=160000000
RCC.HSE_VALUE=8000000
RCC.HSI48_VALUE=48000000
RCC.HSI_VALUE=16000000
RCC.PLLM=RCC_PLLM_DIV2
RCC.PLLN=40
RCC.RTCClockSelection=RCC_RTCCLKSOURCE_LSE
RCC.SYSCLKFreq_VALUE=160000000
RCC.SYSCLKSource=RCC_SYSCLKSOURCE_PLLCLK
RCC.USBFreq_Value=160000000
RCC.VCOOutputFreq_Value=320000000
RTC.Format=RTC_FORMAT_BIN
RTC.StoreOperation=RTC_STOREOPERATION_RESET
SH.COMP_DAC11_group.0=DAC1_OUT1,DAC_OUT1
SH.COMP_DAC12_group.0=DAC1_OUT2,DAC_OUT2
SH.S_TIM16_CH1.0=TIM16_CH1,PWM Generation1 CH1
SH.S_TIM4_CH1.0=TIM4_CH1,Encoder_Interface
SH.S_TIM4_CH2.0=TIM4_CH2,Encoder_Interface
SPI3.BaudRatePrescaler=SPI_BAUDRATEPRESCALER_8
SPI3.CLKPhase=SPI_PHASE_2EDGE
SPI3.CalculateBaudRate=20.0 MBits/s
SPI3.DataSize=SPI_DATASIZE_8BIT
SPI3.Direction=SPI_DIRECTION_2LINES
SPI3.Mode=SPI_MODE_MASTER
SPI3.VirtualType=VM_MASTER
SPI4.BaudRatePrescaler=SPI_BAUDRATEPRESCALER_4
SPI4.CalculateBaudRate=40.0 MBits/s
SPI4.DataSize=SPI_DATASIZE_16BIT
SPI4.Direction=SPI_DIRECTION_2LINES
SPI4.Mode=SPI_MODE_MASTER
SPI4.NSSPMode=SPI_NSS_PULSE_DISABLE
SPI4.VirtualType=VM_MASTER
SYS.VoltageScaling=SYSCFG_VREFBUF_VOLTAGE_SCALE1
TIM16.AutomaticOutput=TIM_AUTOMATICOUTPUT_ENABLE
TIM16.Channel=TIM_CHANNEL_1
TIM16.OCFastMode_PWM=TIM_OCFAST_ENABLE
TIM16.PeriodNoDither=19
TIM16.PulseNoDither_1=10
TIM2.AutoReloadPreload=TIM_AUTORELOAD_PRELOAD_ENABLE
TIM2.PeriodNoDither=199
TIM2.Prescaler=15999
TIM4.IC1Filter=15
TIM4.IC1Polarity=TIM_ICPOLARITY_FALLING
TIM4.IC2Filter=15
TIM4.PeriodNoDither=127
TIM6.AutoReloadPreload=TIM_AUTORELOAD_PRELOAD_ENABLE
TIM6.PeriodNoDither=4999
TIM6.Prescaler=15999
USART2.FIFOMode=FIFOMODE_ENABLE
USART2.VirtualMode-Asynchronous=VM_ASYNC
VP_ADC5_TempSens_Input.Mode=IN-TempSens
VP_ADC5_Vbat_Input.Mode=IN-Vbat
VP_ADC5_Vref_Input.Mode=IN-Vrefint
VP_HRTIM1_VS_hrtimMasterTimerNoOutput.Mode=MasterTimer
VP_HRTIM1_VS_hrtimTimerDNoOutput.Mode=No_output_TD
VP_RTC_VS_RTC_Activate.Mode=RTC_Enabled
VP_RTC_VS_RTC_Calendar.Mode=RTC_Calendar
VP_SYS_VS_DBSignals.Mode=DisableDeadBatterySignals
VP_TIM16_VS_ClockSourceINT.Mode=Enable_Timer
VP_TIM2_VS_ClockSourceINT.Mode=Internal
VP_TIM6_VS_ClockSourceINT.Mode=Enable_Timer
VREF+.GPIO_Label=VREF_UC
VREF+.Mode=InternalMode
VREF+.Signal=VREFBUF_OUT
board=custom

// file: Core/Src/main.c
/* USER CODE BEGIN Header */
/**
  ******************************************************************************
  * @file           : main.c
  * @brief          : Main program body
  ******************************************************************************
  * @attention
  *
  * Copyright (c) 2026 STMicroelectronics.
  * All rights reserved.
  *
  * This software is licensed under terms that can be found in the LICENSE file
  * in the root directory of this software component.
  * If no LICENSE file comes with this software, it is provided AS-IS.
  *
  ******************************************************************************
  */
/* USER CODE END Header */
#include "main.h"
#include "adc.h"
#include "dac.h"
#include "dma.h"
#include "hrtim.h"
#include "i2c.h"
#include "quadspi.h"
#include "rtc.h"
#include "spi.h"
#include "tim.h"
#include "usart.h"
#include "gpio.h"

/* USER CODE BEGIN Includes */
#include "driver_pca9554.h"
#include "aux_io_ctrl.h"
#include "bq76905.h"
#include "bq76905_config.h"
#include "ctrl_main.h"
#include "timer.h"
#include "display.h"
#include "opt3004.h"
#include "lp581x.h"
#include "ui_ctrl.h"
#include "statemachine.h"
#include "cli.h"
#include "config_store.h"
#include <stdio.h>
#include "stdint.h"
#include "lcd.h"
#include "w25n01gv.h"
#include "icon_store.h"
#include "ads131m04.h"
#include "stopwatch.h"
#include "protection.h"
#include "splash.h"
#include "watchdog.h"
#include "fault.h"
#include "error.h"
#include "version.h"
/* USER CODE END Includes */

/* USER CODE BEGIN PV */
BQ76905_handle bms;
ADC_MEAS_DATA adc_data;
ADS131M04_handle ext_adc;
w25n01gv_handle flash;
w25n01gv_status_t flash_status = W25N01GV_OK;

/* USER CODE END PV */

void SystemClock_Config(void);

/* USER CODE BEGIN 0 */
/* main() lives here, not in the generated part: the .ioc has NoMain set,
 * so CubeMX never touches it (and gpio_turnOn() can sit right after
 * MX_GPIO_Init()). */
int main(void)
{

	EVENT_STRUCT e;

  /* MCU Configuration--------------------------------------------------------*/

  /* Reset of all peripherals, Initializes the Flash interface and the Systick. */
  HAL_Init();

  /* Configure the system clock */
  SystemClock_Config();

  /* Initialize all configured peripherals */
  MX_GPIO_Init();

  gpio_turnOn();

  MX_DMA_Init();
  MX_HRTIM1_Init();
  MX_QUADSPI1_Init();
  MX_SPI4_Init();
  MX_ADC1_Init();
  MX_ADC2_Init();
  MX_ADC3_Init();
  MX_ADC4_Init();
  MX_ADC5_Init();
  MX_DAC1_Init();
  MX_SPI3_Init();
  MX_I2C4_Init();
  MX_TIM4_Init();
  MX_TIM16_Init();
  MX_USART2_UART_Init();
  MX_RTC_Init();
  MX_TIM2_Init();
  MX_TIM6_Init();

  dma_irq_priority_override();
  gpio_irq_priority_override();

  LCD_init();
  splash_show();

  event_Init();
  error_Init();

  /*
   * Setup internal timer structure
   */
  timer_init();

  /*
   * DAC test setup
   */
  dac_setValueRef2(2048);
  dac_sqwave_init(DAC_CHANNEL_2, 0); // high value set by dac_sqwave_start()

  /*
   * CLI Setup
   */
  cli_init(&huart2);
  printf("FW %d.%d %s %s\r\n", FW_VERSION_MAJOR, FW_VERSION_MINOR, GIT_HASH, GIT_DATE);
  fault_report_reset();

  /*
   * Init UI control (LEDs)
   */
  ui_ctrl_init();

  /*
   * Load calibration / ID data from EEPROM (or default it, on first
   * boot / missing chip). Must run before adc_init() and
   * ctrl_main_init() so both see the loaded calibration.
   */
  config_store_init();

  /*
   * ADC Init
   */
  adc_init(ext_adc.channelData);
  ADS131M04_init(&ext_adc, &hspi3, SPI_CS_GPIO_Port, SPI_CS_Pin, ADC_SYNC_RESET_N_GPIO_Port, ADC_SYNC_RESET_N_Pin);
  adc_configure_mode(STATEMACHINE_MODE_10A_OUT);
  adc_start();
  /*
   * Wakeup BMS and configure if necessary
   */
  GPIO_SET_BMS_CTRL_WAKEUP(1);
  HAL_Delay(100);
  GPIO_SET_BMS_CTRL_WAKEUP(0);
  BQ76905_init(&bms, BQ76905_I2C_ADDRESS);
  bms.battery_capacity_mAs = config_store.calibration.battery_capacity_mAs;
  if (config_store.soc.valid)
  {
    bms.restore_mAs = config_store.soc.charge_mAs;
    bms.restore_offset_mAs = config_store.soc.offset_mAs;
    bms.restore_pending = 1;
  }

  // HRTIM counters run, outputs stay disabled until a mode starts
  hrtim_start_timer();
  timer_start();

  /*
   * QSPI flash memory init
   */
  flash_status = w25n01gv_init(&flash, &hqspi1, 1000);
  if (flash_status != W25N01GV_OK) {
    printf("Flash initialisation failed!\r\n");
  }
  icon_store_init(); // safe even if flash init failed above -- just reports unavailable

  protection_init();
  ctrl_main_init();
  statemachine_init();

  /*
   * Start the watchdog last: it can't be stopped once running, and everything
   * above (splash, flash/BMS init, 100 ms waits) would otherwise need kicks.
   */
  watchdog_init();

  /* Infinite loop */
  while (1)
  {
	  watchdog_kick();

	  cli_loop();
	  error_Work();

	  // Drain the queue: one event per pass let events pile up behind the CLI.
	  while ((e = event_Get()).event != EVENT_VOID) {
		  switch(e.event){
			case EVENT_VOID:
			case EVENT_INIT:
				break;
			case EVENT_IIC_RX:
			case EVENT_IIC_TX:
				if(e.callback != 0)
					e.callback(e.argument);
				break;
			case EVENT_IIC_ERROR:
				if(e.callback != 0)
					e.callback(e.argument);
				break;
			case EVENT_EEPROM_READ:
				break;
			case EVENT_EEPROM_TIMEOUT:
				break;
			case EVENT_SM_STEP:
				statemachine_step();
				break;
			case EVENT_BMS_TIMER:
				BQ76905_readAllValuesAsync(&bms);
				break;
			case EVENT_EVENT:
			default:
				break;

		  }
		  // One step per pass: a step longer than the 20 ms tick re-queues the
		  // next one, and draining it here would never reach the watchdog kick.
		  if (e.event == EVENT_SM_STEP)
			  break;
	  }

  }
}

/* USER CODE END 0 */

void SystemClock_Config(void)
{
  RCC_OscInitTypeDef RCC_OscInitStruct = {0};
  RCC_ClkInitTypeDef RCC_ClkInitStruct = {0};

  /** Configure the main internal regulator output voltage
  */
  HAL_PWREx_ControlVoltageScaling(PWR_REGULATOR_VOLTAGE_SCALE1_BOOST);

  /** Configure LSE Drive Capability
  */
  HAL_PWR_EnableBkUpAccess();
  __HAL_RCC_LSEDRIVE_CONFIG(RCC_LSEDRIVE_LOW);

  /** Initializes the RCC Oscillators according to the specified parameters
  * in the RCC_OscInitTypeDef structure.
  */
  RCC_OscInitStruct.OscillatorType = RCC_OSCILLATORTYPE_HSI|RCC_OSCILLATORTYPE_LSE;
  RCC_OscInitStruct.LSEState = RCC_LSE_ON;
  RCC_OscInitStruct.HSIState = RCC_HSI_ON;
  RCC_OscInitStruct.HSICalibrationValue = RCC_HSICALIBRATION_DEFAULT;
  RCC_OscInitStruct.PLL.PLLState = RCC_PLL_ON;
  RCC_OscInitStruct.PLL.PLLSource = RCC_PLLSOURCE_HSI;
  RCC_OscInitStruct.PLL.PLLM = RCC_PLLM_DIV2;
  RCC_OscInitStruct.PLL.PLLN = 40;
  RCC_OscInitStruct.PLL.PLLP = RCC_PLLP_DIV2;
  RCC_OscInitStruct.PLL.PLLQ = RCC_PLLQ_DIV2;
  RCC_OscInitStruct.PLL.PLLR = RCC_PLLR_DIV2;
  if (HAL_RCC_OscConfig(&RCC_OscInitStruct) != HAL_OK)
  {
    Error_Handler();
  }

  /** Initializes the CPU, AHB and APB buses clocks
  */
  RCC_ClkInitStruct.ClockType = RCC_CLOCKTYPE_HCLK|RCC_CLOCKTYPE_SYSCLK
                              |RCC_CLOCKTYPE_PCLK1|RCC_CLOCKTYPE_PCLK2;
  RCC_ClkInitStruct.SYSCLKSource = RCC_SYSCLKSOURCE_PLLCLK;
  RCC_ClkInitStruct.AHBCLKDivider = RCC_SYSCLK_DIV1;
  RCC_ClkInitStruct.APB1CLKDivider = RCC_HCLK_DIV1;
  RCC_ClkInitStruct.APB2CLKDivider = RCC_HCLK_DIV1;

  if (HAL_RCC_ClockConfig(&RCC_ClkInitStruct, FLASH_LATENCY_4) != HAL_OK)
  {
    Error_Handler();
  }
}

/* USER CODE BEGIN 4 */
/**
 * External ADC finished SPI communication
 */
void HAL_SPI_TxRxCpltCallback(SPI_HandleTypeDef *hspi) {
	if (hspi == ext_adc.hspi) {
		ADS131M04_handleSPIComplete(&ext_adc);
		stopwatch_sample(adc_v_term_ext_mv_now(), HAL_GetTick());
	}
}

/**
 * Interrupt for external ADC
 */
void HAL_GPIO_EXTI_Callback(uint16_t GPIO_Pin) {
	if (GPIO_Pin == ADC_DRDY_N_Pin) {
		ADS131M04_handleDRDYInterrupt(&ext_adc);
	} else {
		// __NOP();
	}
}
/* USER CODE END 4 */

void Error_Handler(void)
{
  /* USER CODE BEGIN Error_Handler_Debug */
	fault_halt("Error_Handler", (uint32_t) __builtin_return_address(0));
  /* USER CODE END Error_Handler_Debug */
}
